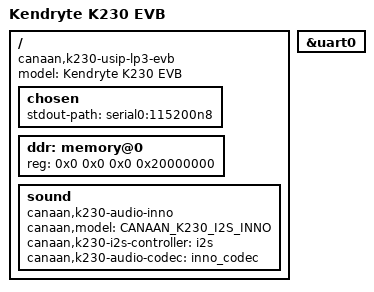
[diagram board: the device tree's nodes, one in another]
// SPDX-License-Identifier: GPL-2.0 OR MIT
/*
 * Copyright (C) 2024 Yangyu Chen <cyy@cyyself.name>
 */

#include "k230.dtsi"

/ {
	model = "Kendryte K230 EVB";
	compatible = "canaan,k230-usip-lp3-evb", "canaan,kendryte-k230";

	chosen {
		stdout-path = "serial0:115200n8";
	};

	ddr: memory@0 {
		device_type = "memory";
		reg = <0x0 0x0 0x0 0x20000000>;
	};

	sound {
		status                      = "okay";
		compatible                  = "canaan,k230-audio-inno";
		canaan,model                = "CANAAN_K230_I2S_INNO";
		canaan,k230-i2s-controller  = <&i2s>;
		canaan,k230-audio-codec     = <&inno_codec>;
	};
};

&uart0 {
	status = "okay";
};
